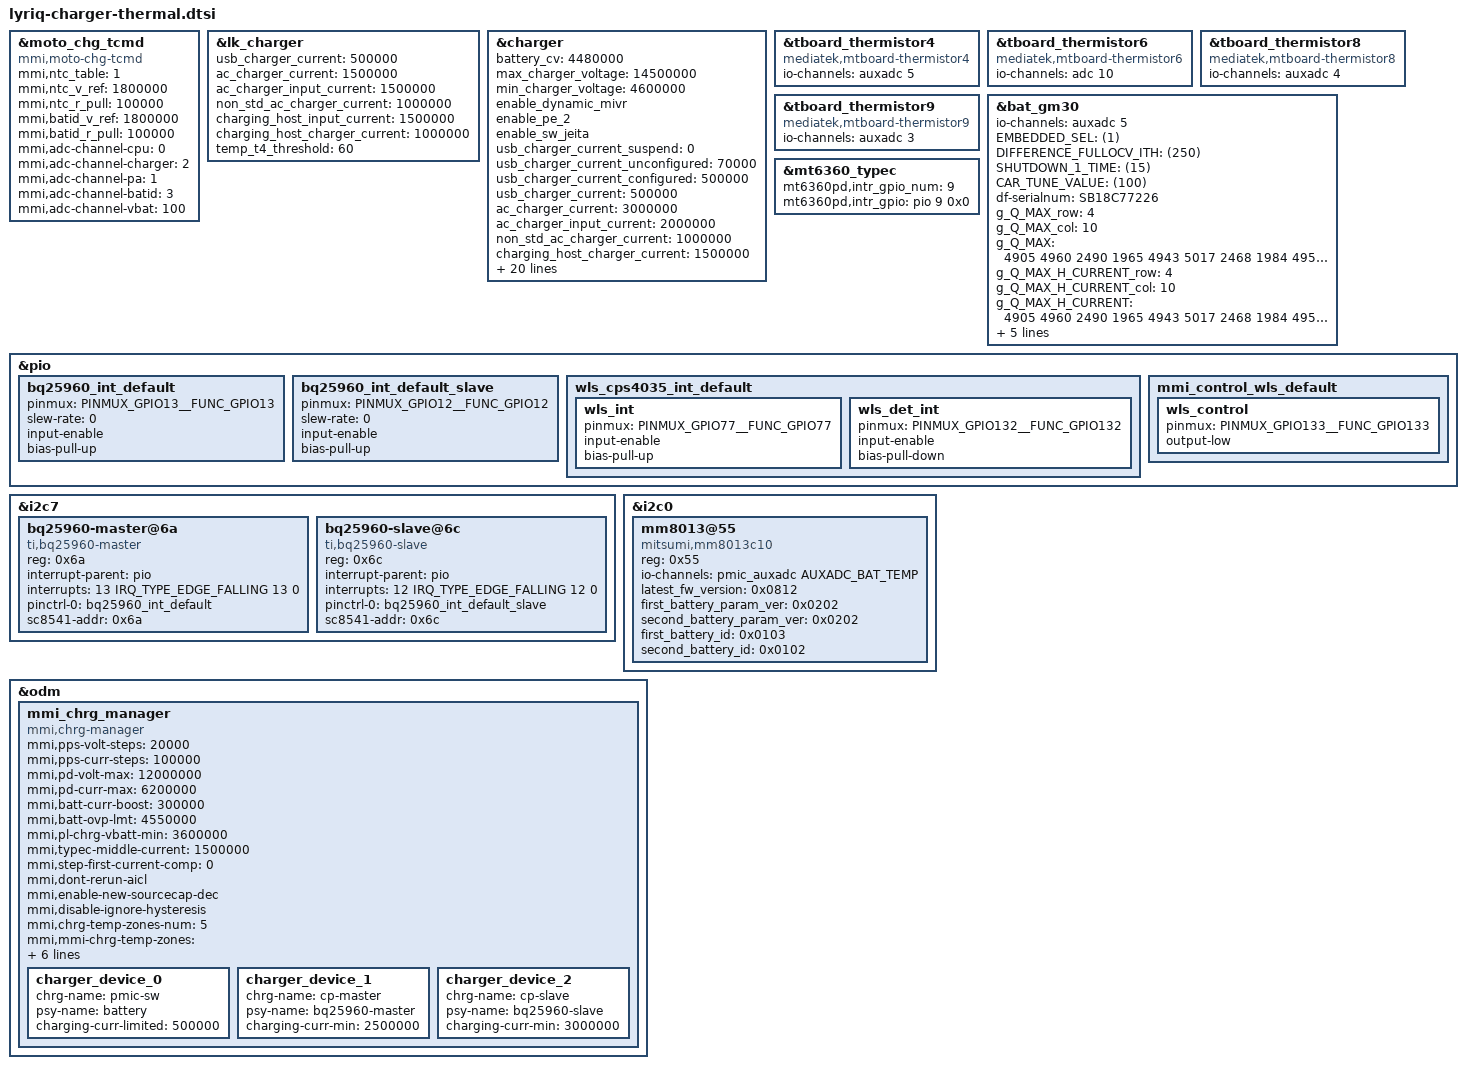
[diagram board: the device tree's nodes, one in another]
/*
 * Copyright (c) 2019 MediaTek Inc.
 *
 * This program is free software; you can redistribute it and/or modify
 * it under the terms of the GNU General Public License version 2 as
 * published by the Free Software Foundation.
 *
 * This program is distributed in the hope that it will be useful,
 * but WITHOUT ANY WARRANTY; without even the implied warranty of
 * MERCHANTABILITY or FITNESS FOR A PARTICULAR PURPOSE.  See the
 * GNU General Public License for more details.
 */
#include <dt-bindings/iio/mt635x-auxadc.h>
&moto_chg_tcmd {
                compatible = "mmi,moto-chg-tcmd";
                status = "okay";

                mmi,ntc_table = <1>;
                mmi,ntc_v_ref = <1800000>;
                mmi,ntc_r_pull = <100000>;

                mmi,batid_v_ref = <1800000>;
                mmi,batid_r_pull = <100000>;

                mmi,adc-channel-cpu = <0>;
                mmi,adc-channel-charger = <2>;
                mmi,adc-channel-pa = <1>;
                mmi,adc-channel-batid = <3>;
                mmi,adc-channel-vbat = <100>;
};

&lk_charger {
        /* charging current */
        usb_charger_current = <500000>;
        ac_charger_current = <1500000>;
        ac_charger_input_current = <1500000>;
        non_std_ac_charger_current = <1000000>;
        charging_host_input_current = <1500000>;
        charging_host_charger_current = <1000000>;

        temp_t4_threshold = <60>;
};

&charger {
        /* common */
        battery_cv = <4480000>;
        max_charger_voltage = <14500000>;
        min_charger_voltage = <4600000>;
	enable_dynamic_mivr;
        enable_pe_2;
        enable_sw_jeita;

        /* charging current */
        usb_charger_current_suspend = <0>;
        usb_charger_current_unconfigured = <70000>;
        usb_charger_current_configured = <500000>;
        usb_charger_current = <500000>;
        ac_charger_current = <3000000>;
        ac_charger_input_current = <2000000>;
        non_std_ac_charger_current = <1000000>;
        charging_host_charger_current = <1500000>;
        apple_1_0a_charger_current = <650000>;
        apple_2_1a_charger_current = <800000>;
        ta_ac_charger_current = <2000000>;
        typec_limit_aicr = <2000000>;

        wireless_factory_max_current = <3000000>;
        wireless_factory_max_input_current = <600000>;

        //mmi config
        mmi,iterm-ma = <215>;
        mmi,mmi-temp-zones =
                       <0 4200 800  0>,
                       <10 4250 4000 2000>,
                       <15 0 4000 4000>,
                       <25 4250 12400 6000>,
                       <35 4250 12400 6000>,
                       <45 4250 12400 6000>,
                       <60 4200 4000 0>;

	mmi,mmi-ffc-zones =
                        <4200 215>,
                        <4450 215>,
                        <4450 215>,
                        <4480 712>,
                        <4480 816>,
                        <4480 952>,
                        <4200 215>;

        mmi,enable-charging-limit;
        mmi,upper-limit-capacity = <65>;
        mmi,lower-limit-capacity = <60>;
        mmi,vfloat-comp-uv = <20000>;
	enable_cp;
        mmi,min-cp-therm-current-ua = <1600000>;
};

&tboard_thermistor4 {
	compatible = "mediatek,mtboard-thermistor4";
	io-channels = <&auxadc 5>;
	io-channel-names = "thermistor-ch3";
};

&tboard_thermistor6 {
	compatible = "mediatek,mtboard-thermistor6";
	io-channels = <&adc 10>;
	io-channel-names = "thermistor-ch5";
};

&tboard_thermistor8 {
	compatible = "mediatek,mtboard-thermistor8";
	io-channels = <&auxadc 4>;
	io-channel-names = "thermistor-ch7";
};

&tboard_thermistor9 {
	compatible = "mediatek,mtboard-thermistor9";
	io-channels = <&auxadc 3>;
	io-channel-names = "thermistor-ch8";
};

&bat_gm30 {
        io-channels = <&auxadc 5>;
        io-channel-names = "batteryID-channel";
        EMBEDDED_SEL = <(1)>;   /* embedded battery.*/
        DIFFERENCE_FULLOCV_ITH = <(250)>;       /*Charging termination current.*/
        SHUTDOWN_1_TIME = <(15)>;
        CAR_TUNE_VALUE = <(100)>;

        df-serialnum = "SB18C77226";
        g_Q_MAX_row = <4>;
        g_Q_MAX_col = <10>;
        g_Q_MAX = <
                /*bat1,   bat2,   bat3,    bat4*/
                4905 4960 2490 1965/*T0*/
                4943 5017 2468 1984/*T1*/
                4955 5033 2310 1946/*T2*/
                4936 5009 1858 1873/*T3*/
                4937 5007 1843 1851/*T4*/
                4937 5007 1533 1541/*T5*/
                4937 5007 1523 1531/*T6*/
                4937 5007 1513 1521/*T7*/
                4937 5007 1503 1511/*T8*/
                4937 5007 1493 1501/*T9*/
        >;
        g_Q_MAX_H_CURRENT_row = <4>;
        g_Q_MAX_H_CURRENT_col = <10>;
        g_Q_MAX_H_CURRENT = <
                /*bat1,   bat2,   bat3,    bat4*/
                4905 4960 2490 1965/*T0*/
                4943 5017 2468 1984/*T1*/
                4955 5033 2310 1946/*T2*/
                4936 5009 1858 1873/*T3*/
                4937 5007 1843 1851/*T4*/
                4937 5007 1533 1541/*T5*/
                4937 5007 1523 1531/*T6*/
                4937 5007 1513 1521/*T7*/
                4937 5007 1503 1511/*T8*/
                4937 5007 1493 1501/*T9*/
        >;
        g_FG_PSEUDO100_T0 = <(98)>;
/*      Pseudo 100% percentage at T0*/
        g_FG_PSEUDO100_T1 = <(98)>;
/*      Pseudo 100% percentage at T1*/
        g_FG_PSEUDO100_T2 = <(95)>;
/*      Pseudo 100% percentage at T2*/
        g_FG_PSEUDO100_T3 = <(95)>;
/*      Pseudo 100% percentage at T3*/
        g_FG_PSEUDO100_T4 = <(95)>;
/*      Pseudo 100% percentage at T4*/
        #include "bat_setting/austin_batterytable_jk50_alt_5000mah.dtsi"
        #include "bat_setting/austin_batterytable_jk50_scud_5000mah.dtsi"
};

&mt6360_typec {
        mt6360pd,intr_gpio_num = <9>;
        mt6360pd,intr_gpio = <&pio 9 0x0>;
};
/*
&pdc {
        sc_input_current = <3000000>;
};

&pe2 {
        sc_input_current = <3000000>;
};

&mtk_ctd {
        bootmode = <&chosen>;
};
*/
&pio {
        bq25960_int_default: bq25960_int_default {
                pinmux = <PINMUX_GPIO13__FUNC_GPIO13>;
                slew-rate= <0>;
                input-enable;
                bias-pull-up;
        };

	bq25960_int_default_slave: bq25960_int_default_slave {
                pinmux = <PINMUX_GPIO12__FUNC_GPIO12>;
                slew-rate= <0>;
                input-enable;
                bias-pull-up;
        };

        wls_cps4035_int_default: wls_cps4035_int_default {
                wls_int {
                        pinmux = <PINMUX_GPIO77__FUNC_GPIO77>;
                        input-enable;
                        bias-pull-up;
                };
                wls_det_int {
                        pinmux = <PINMUX_GPIO132__FUNC_GPIO132>;
                        input-enable;
                        bias-pull-down;
                };
        };
/*
        mmi_mux_wls_default: mmi_mux_wls_default {
                wls_switch {
                        pinmux = <PINMUX_GPIO104__FUNC_GPIO104>;
                        output-low;
                };
                wls_boost {
                        pinmux = <PINMUX_GPIO121__FUNC_GPIO121>;
                        output-low;
                };
        };
*/
        mmi_control_wls_default: mmi_control_wls_default {
                wls_control {
                        pinmux = <PINMUX_GPIO133__FUNC_GPIO133>;
                        output-low;
                };
        };
};

&i2c7 {
        status = "okay";

        bq25960-master@6a {
                compatible = "ti,bq25960-master";
                reg = <0x6a>;

                interrupt-parent = <&pio>;
                interrupts = <13 IRQ_TYPE_EDGE_FALLING 13 0>;
                interrupt-names = "bq25960_irq";
                pinctrl-names = "default";
                pinctrl-0 = <&bq25960_int_default>;

                sc8541-addr = <0x6a>;
        };

        bq25960-slave@6c {
                compatible = "ti,bq25960-slave";
                reg = <0x6c>;

                interrupt-parent = <&pio>;
                interrupts = <12 IRQ_TYPE_EDGE_FALLING 12 0>;
                interrupt-names = "bq25960_irq";
                pinctrl-names = "default_slave";
                pinctrl-0 = <&bq25960_int_default_slave>;

                sc8541-addr = <0x6c>;
        };
};

&i2c0 {
        status = "okay";

	mm8013@55 {
		compatible = "mitsumi,mm8013c10";
		reg = <0x55>;
		//status = "okay";
		io-channels = <&pmic_auxadc AUXADC_BAT_TEMP>;
		io-channel-names = "batt_therm";

		latest_fw_version = <0x0812>;
		first_battery_param_ver = <0x0202>;
		second_battery_param_ver = <0x0202>;

		first_battery_id = <0x0103>;
		second_battery_id = <0x0102>;
	};
};

&odm {
         status = "okay";

        mmi_chrg_manager {
                status = "ok";
                compatible = "mmi,chrg-manager";
                mmi,pps-volt-steps = <20000>;
                mmi,pps-curr-steps = <100000>;
                mmi,pd-volt-max = <12000000>;
                mmi,pd-curr-max = <6200000>;
                mmi,batt-curr-boost = <300000>;
                mmi,batt-ovp-lmt = <4550000>;
                mmi,pl-chrg-vbatt-min = <3600000>;
                mmi,typec-middle-current = <1500000>;
                mmi,step-first-current-comp = <0>;
                mmi,dont-rerun-aicl;
                mmi,enable-new-sourcecap-dec;
                mmi,disable-ignore-hysteresis;
                mmi,chrg-temp-zones-num = <5>;
                mmi,mmi-chrg-temp-zones =
                                        <0 4200 800  0 0 0 0 0 0>,
                                        <10 4250 4000 4480 2000 0 0 0 0>,
                                        <15 4480 4000 0 0 0 0 0 0>,
                                        <45 4250 12400 4300 8000 4480 6000 4510 4000>,
                                        <60 4200 4000 0 0 0 0 0 0>;
                mmi,thermal-min-level = <2000000>;
                charger_device_0 {
                        chrg-name = "pmic-sw";
                        psy-name = "battery";
                        charging-curr-limited = <500000>;
                };
                charger_device_1 {
                        chrg-name = "cp-master";
                        psy-name = "bq25960-master";
                        charging-curr-min = <2500000>;
                };
                charger_device_2 {
                        chrg-name = "cp-slave";
                        psy-name = "bq25960-slave";
                        charging-curr-min = <3000000>;
                };

        };
};
/*
&i2c4 {
	cps-wls-charger@38 {
		compatible = "cps,wls-charger-cps4038";
		reg = <0x38>;
		bootmode = <&chosen>;
		charger = <&mt6360_chg>;
		wireless-fw-name = "cps4038.bin";
		cps_wls_int = <&pio 77 0x00>;
		cps_det_int = <&pio 132 0x0>;
		pinctrl-names = "default";
		pinctrl-0 = <&wls_cps4035_int_default>;
		//interrupt-names = "cps_wls_int";
		#cooling-cells = <2>;
        	status = "okay";
	};
};

&moto_wlc {
        compatible = "moto,charger,wlc";
        gauge = <&bat_gm30>;
        min_charger_voltage = <4600000>;
        wlc_max_charger_current = <3150000>;
        wlc_max_input_current = <1150000>;
        mmi,wls_control_en = <&pio 133 0x0>;//wlc_inhibit
        pinctrl-names = "default";
        pinctrl-0 = <&mmi_control_wls_default>;
        #cooling-cells = <2>;
        mmi,wlc-rx-mitigation = <(-1) 2500000 2000000 1500000 1200000
                                1000000 700000 500000>;
};
*/
